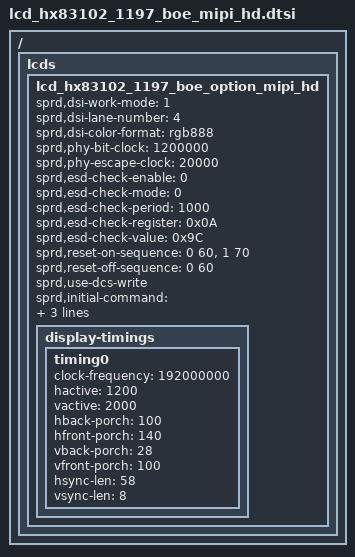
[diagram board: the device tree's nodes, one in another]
/*
 * tv105wum LCD config dtsi file for spreadtrum
 *
 * Copyright (C) 2018, Spreadtrum Communications Inc.
 * Copyright (C) 2023 Anhui Yunshu Zhihui Technology Co., Ltd.
 *
 * SPDX-License-Identifier: (GPL-2.0+ OR MIT)
 */

/ { lcds {
	lcd_hx83102_1197_boe_option_mipi_hd: lcd_hx83102_1197_boe_option_mipi_hd {

		sprd,dsi-work-mode = <1>; /* video burst mode*/
		sprd,dsi-lane-number = <4>;
		sprd,dsi-color-format = "rgb888";

		sprd,phy-bit-clock = <1200000>;	/* kbps */
		sprd,phy-escape-clock = <20000>;/* kHz */

		/*
		sprd,width-mm = <68>;
		sprd,height-mm = <121>;
		*/

		sprd,esd-check-enable = <0>;
		sprd,esd-check-mode = <0>;
		sprd,esd-check-period = <1000>;
		sprd,esd-check-register = <0x0A>;
		sprd,esd-check-value = <0x9C>;

		sprd,reset-on-sequence = <0 60>, <1 70>;
		sprd,reset-off-sequence = <0 60>;

		sprd,use-dcs-write;
		sprd,initial-command = [
			39 00 00 06 B9 83 10 21 55 00
			39 00 00 1b B1 2C B1 B1 2D ED 42 E1 4D 36 36 36 36 1A 8B 11 65 00 88 FA FF FF 8F FF 08 9A 33
			39 00 00 10 B2 00 47 B0 D0 00 22 62 3C 9B 32 30 00 00 88 F5
			39 00 00 0d B4 3C 3C 3C 3C 3C 3C 5F 49 7C 70 01 96
			15 00 00 02 E9 CD
			15 00 00 02 BA 84
			15 00 00 02 E9 3F
			39 00 00 03 BC 1B 04
			15 00 00 02 BE 20
			39 00 00 0b C0 3A 3A 22 11 22 A0 61 08 F5 03
			15 00 00 02 E9 CC
			15 00 00 02 C7 80
			15 00 00 02 E9 3F
			15 00 00 02 E9 C6
			15 00 00 02 C8 97
			15 00 00 02 E9 3F
			39 00 00 06 C9 00 1E 13 88 01
			39 00 00 07 CB 08 13 07 00 0E A1
			39 00 00 04 CC 02 03 44
			15 00 00 02 E9 C4
			15 00 00 02 D0 03
			15 00 00 02 E9 3F
			39 00 00 08 D1 37 06 00 02 04 0C FF
			39 00 00 23 D3 06 00 00 00 40 04 08 04 08 27 47 43 3B 20 20 03 03 32 10 1C 00 1C 32 10 19 00 19 32 17 F5 07 F5 00 00
			39 00 00 2d D5 18 18 18 18 1F 1F 1F 1F 1E 1E 1E 1E 24 24 24 24 01 00 01 00 03 02 03 02 05 04 05 04 07 06 07 06 21 20 21 20 18 18 18 18 18 18 18 18
			39 00 00 0d D8 AF AF AA AA AA A0 AF AF AA AA AA A0
			39 00 00 2F E0 00 05 0E 14 1C 2F 47 4E 57 53 6F 76 7D 8C 89 8F 95 A3 9D 4A 50 57 73 00 05 0E 14 1C 2F 47 4E 57 53 6F 76 7D 8C 89 8F 95 A3 9D 4A 50 57 73
			39 00 00 18 E7 04 10 10 27 2C 96 02 BA 46 14 14 00 00 00 00 12 05 02 02 10 33 03 84
			15 00 00 02 BD 01
			39 00 00 04 B1 01 BF 11
			15 00 00 02 CB 86
			15 00 00 02 D2 78
			15 00 00 02 E9 C9
			15 00 00 02 D3 84
			15 00 00 02 E9 3F
			39 00 00 25 D8 FF FF FF FF FA A0 FF FF FF FF FA A0 FF FF FF FF FA A0 FF FF FF FF FA A0 FF FF FF FF FA A0 FF FF FF FF FA A0
			39 00 00 0c E7 02 00 3D 01 83 0F 80 10 A0 00 00
			15 00 00 02 BD 02
			39 00 00 0d D8 FF FF FF FF FA A0 FF FF FF FF FA A0
			39 00 00 1d E7 FE 03 FE 03 FE 03 02 02 02 25 00 25 81 02 40 00 20 96 04 03 02 01 00 00 00 00 01 00
			15 00 00 02 BD 03
			39 00 00 25 D8 AA AF AA AA AA A0 AA AF AA AA AA A0 AA AF AA AA AA A0 AA AF AA AA AA A0 55 55 55 55 55 50 55 55 55 55 55 50
			15 00 00 02 E1 00
			15 00 00 02 BD 00
			15 00 00 02 E9 C4
			15 00 00 02 BA 96
			15 00 00 02 E9 3F
			15 00 00 02 BD 01
			15 00 00 02 E9 C5
			15 00 00 02 BA 4F
			15 00 00 02 E9 3F
			15 00 00 02 BD 03
			15 00 00 02 E9 C6
			39 00 00 04 B4 03 FF F8
			15 00 00 02 E9 3F
			15 00 00 02 BD 00
			39 00 00 06 B9 00 00 00 00 00
			05 78 00 01 11
			05 14 00 01 29
			];

		sprd,sleep-in-command = [
			05 0A 00 01 28
			05 65 00 01 10
			];

/*		sprd,sleep-out-command = [
			13 64 00 01 11
			13 32 00 01 29
			]; */

		display-timings {
			timing0 {
				clock-frequency = <192000000>;
				hactive = <1200>;
				vactive = <2000>;
				hback-porch = <100>;
				hfront-porch = <140>;
				vback-porch = <28>;
				vfront-porch = <100>;
				hsync-len = <58>;
				vsync-len = <8>;
			};
		};
	};
};};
